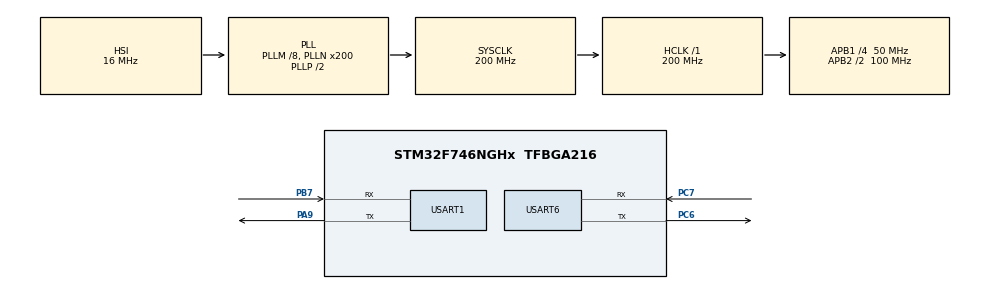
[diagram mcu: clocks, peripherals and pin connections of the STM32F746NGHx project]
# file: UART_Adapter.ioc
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Mcu.Family=STM32F7
Mcu.Name=STM32F746NGHx
Mcu.Package=TFBGA216
NVIC.PriorityGroup=NVIC_PRIORITYGROUP_4
NVIC.USART1_IRQn=true\:0\:0\:false\:false\:true\:true\:true\:true
NVIC.USART6_IRQn=true\:0\:0\:false\:false\:true\:true\:true\:true
PA9.Mode=Asynchronous
PA9.Signal=USART1_TX
PB7.Mode=Asynchronous
PB7.Signal=USART1_RX
PC6.Mode=Asynchronous
PC6.Signal=USART6_TX
PC7.Mode=Asynchronous
PC7.Signal=USART6_RX
ProjectManager.HeapSize=0x200
ProjectManager.StackSize=0x400
ProjectManager.TargetToolchain=STM32CubeIDE
RCC.AHBFreq_Value=200000000
RCC.APB1CLKDivider=RCC_HCLK_DIV4
RCC.APB1Freq_Value=50000000
RCC.APB1TimFreq_Value=100000000
RCC.APB2CLKDivider=RCC_HCLK_DIV2
RCC.APB2Freq_Value=100000000
RCC.APB2TimFreq_Value=200000000
RCC.CortexFreq_Value=200000000
RCC.HCLKFreq_Value=200000000
RCC.HSE_VALUE=25000000
RCC.HSI_VALUE=16000000
RCC.LSE_VALUE=32768
RCC.PLLM=8
RCC.PLLN=200
RCC.PLLSourceVirtual=RCC_PLLSOURCE_HSI
RCC.SYSCLKFreq_VALUE=200000000
RCC.SYSCLKSource=RCC_SYSCLKSOURCE_PLLCLK
RCC.USBFreq_Value=200000000
RCC.VCOOutputFreq_Value=400000000
USART1.VirtualMode-Asynchronous=VM_ASYNC
USART6.VirtualMode-Asynchronous=VM_ASYNC
board=STM32F746G-DISCO

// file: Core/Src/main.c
/* USER CODE BEGIN Header */
/**
  ******************************************************************************
  * @file           : main.c
  * @brief          : Main program body
  ******************************************************************************
  * @attention
  *
  * Copyright (c) 2024 STMicroelectronics.
  * All rights reserved.
  *
  * This software is licensed under terms that can be found in the LICENSE file
  * in the root directory of this software component.
  * If no LICENSE file comes with this software, it is provided AS-IS.
  *
  ******************************************************************************
  *
  * PIN D0 (PC7) -> RX
  * PIN D1 (PC6) -> TX
  *
  ******************************************************************************
  */
/* USER CODE END Header */
#include "main.h"

/* USER CODE BEGIN PD */
#define BUF_SIZE 1
/* USER CODE END PD */

UART_HandleTypeDef huart1;
UART_HandleTypeDef huart6;

/* USER CODE BEGIN PV */
uint8_t uart1_buf[BUF_SIZE];
uint8_t uart6_buf[BUF_SIZE];
/* USER CODE END PV */

void SystemClock_Config(void);
static void MX_GPIO_Init(void);
static void MX_USART1_UART_Init(void);
static void MX_USART6_UART_Init(void);

/* USER CODE BEGIN PFP */
void HAL_UART_RxCpltCallback(UART_HandleTypeDef* huart);
/* USER CODE END PFP */

int main(void) {

    /* MCU Configuration--------------------------------------------------------*/

    /* Reset of all peripherals, Initializes the Flash interface and the Systick. */
    HAL_Init();

    /* Configure the system clock */
    SystemClock_Config();

    /* Initialize all configured peripherals */
    MX_GPIO_Init();
    MX_USART1_UART_Init();
    MX_USART6_UART_Init();
    /* USER CODE BEGIN 2 */
    HAL_UART_Receive_IT(&huart1, uart1_buf, BUF_SIZE);
    HAL_UART_Receive_IT(&huart6, uart6_buf, BUF_SIZE);
    /* USER CODE END 2 */

    /* Infinite loop */
    while (1) {

    }
}

void SystemClock_Config(void) {
    RCC_OscInitTypeDef RCC_OscInitStruct = {0};
    RCC_ClkInitTypeDef RCC_ClkInitStruct = {0};

    /** Configure the main internal regulator output voltage
    */
    __HAL_RCC_PWR_CLK_ENABLE();
    __HAL_PWR_VOLTAGESCALING_CONFIG(PWR_REGULATOR_VOLTAGE_SCALE1);

    /** Initializes the RCC Oscillators according to the specified parameters
    * in the RCC_OscInitTypeDef structure.
    */
    RCC_OscInitStruct.OscillatorType = RCC_OSCILLATORTYPE_HSI;
    RCC_OscInitStruct.HSIState = RCC_HSI_ON;
    RCC_OscInitStruct.HSICalibrationValue = RCC_HSICALIBRATION_DEFAULT;
    RCC_OscInitStruct.PLL.PLLState = RCC_PLL_ON;
    RCC_OscInitStruct.PLL.PLLSource = RCC_PLLSOURCE_HSI;
    RCC_OscInitStruct.PLL.PLLM = 8;
    RCC_OscInitStruct.PLL.PLLN = 200;
    RCC_OscInitStruct.PLL.PLLP = RCC_PLLP_DIV2;
    RCC_OscInitStruct.PLL.PLLQ = 2;
    if (HAL_RCC_OscConfig(&RCC_OscInitStruct) != HAL_OK) {
        Error_Handler();
    }

    /** Activate the Over-Drive mode
    */
    if (HAL_PWREx_EnableOverDrive() != HAL_OK) {
        Error_Handler();
    }

    /** Initializes the CPU, AHB and APB buses clocks
    */
    RCC_ClkInitStruct.ClockType = RCC_CLOCKTYPE_HCLK | RCC_CLOCKTYPE_SYSCLK | RCC_CLOCKTYPE_PCLK1 | RCC_CLOCKTYPE_PCLK2;
    RCC_ClkInitStruct.SYSCLKSource = RCC_SYSCLKSOURCE_PLLCLK;
    RCC_ClkInitStruct.AHBCLKDivider = RCC_SYSCLK_DIV1;
    RCC_ClkInitStruct.APB1CLKDivider = RCC_HCLK_DIV4;
    RCC_ClkInitStruct.APB2CLKDivider = RCC_HCLK_DIV2;

    if (HAL_RCC_ClockConfig(&RCC_ClkInitStruct, FLASH_LATENCY_6) != HAL_OK) {
        Error_Handler();
    }
}

static void MX_USART1_UART_Init(void) {

    huart1.Instance = USART1;
    huart1.Init.BaudRate = 115200;
    huart1.Init.WordLength = UART_WORDLENGTH_8B;
    huart1.Init.StopBits = UART_STOPBITS_1;
    huart1.Init.Parity = UART_PARITY_NONE;
    huart1.Init.Mode = UART_MODE_TX_RX;
    huart1.Init.HwFlowCtl = UART_HWCONTROL_NONE;
    huart1.Init.OverSampling = UART_OVERSAMPLING_16;
    huart1.Init.OneBitSampling = UART_ONE_BIT_SAMPLE_DISABLE;
    huart1.AdvancedInit.AdvFeatureInit = UART_ADVFEATURE_NO_INIT;
    if (HAL_UART_Init(&huart1) != HAL_OK) {
        Error_Handler();
    }

}

static void MX_USART6_UART_Init(void) {

    huart6.Instance = USART6;
    huart6.Init.BaudRate = 115200;
    huart6.Init.WordLength = UART_WORDLENGTH_8B;
    huart6.Init.StopBits = UART_STOPBITS_1;
    huart6.Init.Parity = UART_PARITY_NONE;
    huart6.Init.Mode = UART_MODE_TX_RX;
    huart6.Init.HwFlowCtl = UART_HWCONTROL_NONE;
    huart6.Init.OverSampling = UART_OVERSAMPLING_16;
    huart6.Init.OneBitSampling = UART_ONE_BIT_SAMPLE_DISABLE;
    huart6.AdvancedInit.AdvFeatureInit = UART_ADVFEATURE_NO_INIT;
    if (HAL_UART_Init(&huart6) != HAL_OK) {
        Error_Handler();
    }

}

static void MX_GPIO_Init(void) {

    /* GPIO Ports Clock Enable */
    __HAL_RCC_GPIOB_CLK_ENABLE();
    __HAL_RCC_GPIOA_CLK_ENABLE();
    __HAL_RCC_GPIOC_CLK_ENABLE();

}

/* USER CODE BEGIN 4 */
void HAL_UART_RxCpltCallback(UART_HandleTypeDef* huart) {
    if (huart->Instance == USART1) {
        /* PC -> GPIO */
        HAL_UART_Transmit(&huart6, uart1_buf, BUF_SIZE, HAL_MAX_DELAY);
        HAL_UART_Receive_IT(&huart1, uart1_buf, BUF_SIZE);
    } else if (huart->Instance == USART6) {
        /* GPIO -> PC */
        HAL_UART_Transmit(&huart1, uart6_buf, BUF_SIZE, HAL_MAX_DELAY);
        HAL_UART_Receive_IT(&huart6, uart6_buf, BUF_SIZE);
    }
}
/* USER CODE END 4 */

void Error_Handler(void) {
    __disable_irq();
    while (1) {
    }
}
